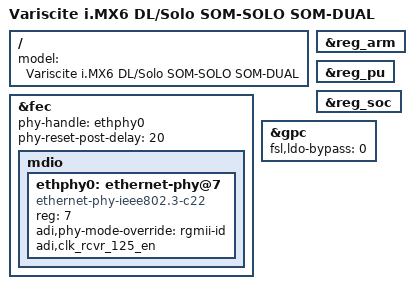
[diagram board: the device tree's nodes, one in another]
/*
 * Copyright (C) 2015-2017 Variscite Ltd.
 *
 * This program is free software; you can redistribute it and/or modify
 * it under the terms of the GNU General Public License version 2 as
 * published by the Free Software Foundation.
 */

#include "imx6dl-var-som.dtsi"

/ {
	model = "Variscite i.MX6 DL/Solo SOM-SOLO SOM-DUAL";
};

&fec {
	/delete-property/ phy-reset-on-resume;
	phy-handle = <&ethphy0>;
	phy-reset-post-delay = <20>;

	mdio {
		#address-cells = <1>;
		#size-cells = <0>;

		ethphy0: ethernet-phy@7 {
			compatible = "ethernet-phy-ieee802.3-c22";
			reg = <7>;
			adi,phy-mode-override = "rgmii-id";
			adi,clk_rcvr_125_en;
		};
	};
};

&reg_arm {
	/delete-property/ vin-supply;
};

&reg_pu {
	/delete-property/ vin-supply;
};

&reg_soc {
	/delete-property/ vin-supply;
};

&gpc {
	/* use ldo-enable, u-boot will check it and configure */
	fsl,ldo-bypass = <0>;
};
